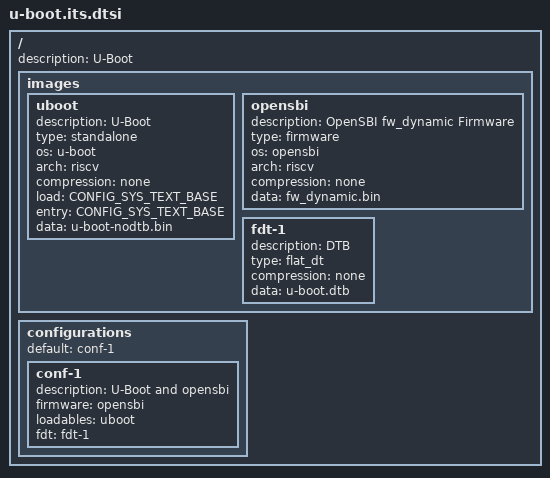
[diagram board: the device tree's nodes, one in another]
/dts-v1/;

/ {
	description = "U-Boot";
	#address-cells = <1>;

	images {
		uboot {
			description = "U-Boot";
			type = "standalone";
			os = "u-boot";
			arch = "riscv";
			compression = "none";
			load = <CONFIG_SYS_TEXT_BASE>;
			entry = <CONFIG_SYS_TEXT_BASE>;
			data = /incbin/("u-boot-nodtb.bin");
		};

		opensbi {
			description = "OpenSBI fw_dynamic Firmware";
			type = "firmware";
			os = "opensbi";
			arch = "riscv";
			compression = "none";
			/* Don't set the load address and entry address for opensbi,
			 * let SPL determine the load address according DRAM size.
			 * load = <CONFIG_SPL_OPENSBI_LOAD_ADDR>;
			 * entry = <CONFIG_SPL_OPENSBI_LOAD_ADDR>;
			 */
			data = /incbin/("fw_dynamic.bin");
		};

		fdt-1{
			description = "DTB";
			type = "flat_dt";
			compression = "none";
			data = /incbin/("u-boot.dtb");
		};
	};

	configurations {
		default = "conf-1";

		conf-1 {
			description = "U-Boot and opensbi";
			firmware = "opensbi";
			loadables = "uboot";
			fdt = "fdt-1";
		};
	};
};
